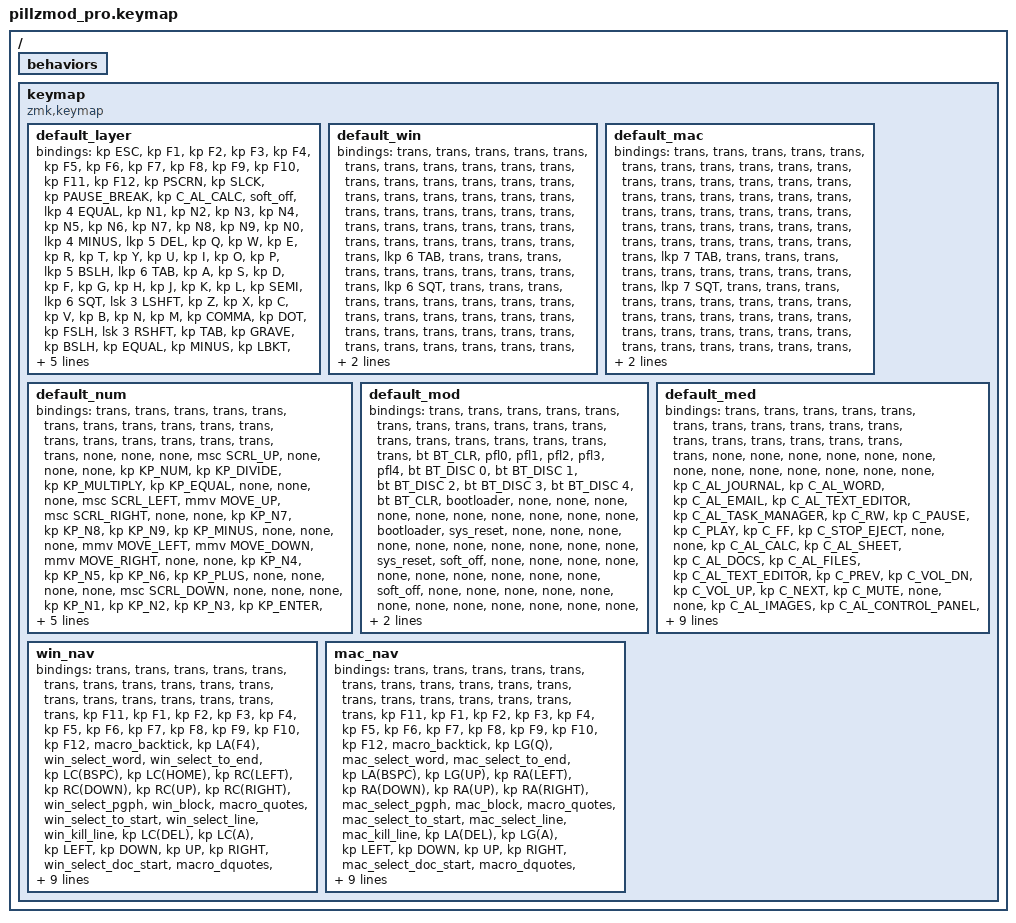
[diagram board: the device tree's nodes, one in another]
#define ZMK_POINTING_DEFAULT_MOVE_VAL 1400  // default: 600
#define ZMK_POINTING_DEFAULT_SCRL_VAL 40    // default: 10
#define USER_CONFIG_DEFAULT_KEYMAP 1        // default: keymaps

#include <behaviors.dtsi>
#include <dt-bindings/zmk/backlight.h>
#include <dt-bindings/zmk/bt.h>
#include <dt-bindings/zmk/keys.h>
#include <dt-bindings/zmk/outputs.h>
#include <dt-bindings/zmk/pointing.h>
#include "plugin/overrides.dtsi"
#include "keys.dtsi"

/ {
    behaviors {
        #include "plugin/definitions.dtsi"
        #include "plugin/declarations.dtsi"
        #include "plugin/macros.dtsi"
        #include "version.dtsi"
    };

    keymap {
        compatible = "zmk,keymap";

        default_layer {
            bindings = <
                &kp  ESC     &kp F1     &kp F2    &kp F3   &kp F4    &kp F5  &kp F6 &kp F7 &kp F8                  &kp F9 &kp F10 &kp F11 &kp F12  &kp PSCRN &kp SLCK   &kp PAUSE_BREAK &kp C_AL_CALC &soft_off
                &lkp 4 EQUAL &kp N1     &kp N2    &kp N3   &kp N4    &kp N5                                                               &kp N6   &kp N7    &kp N8     &kp N9          &kp N0        &lkp 4 MINUS
                &lkp 5 DEL   &kp Q      &kp W     &kp E    &kp R     &kp T                                                                &kp Y    &kp U     &kp I      &kp O           &kp P         &lkp 5 BSLH
                &lkp 6 TAB   &kp A      &kp S     &kp D    &kp F     &kp G                                                                &kp H    &kp J     &kp K      &kp L           &kp SEMI      &lkp 6 SQT
                &lsk 3 LSHFT &kp Z      &kp X     &kp C    &kp V     &kp B                                                                &kp N    &kp M     &kp COMMA  &kp DOT         &kp FSLH      &lsk 3 RSHFT
                             &kp TAB    &kp GRAVE &kp BSLH &kp EQUAL                                                                               &kp MINUS &kp LBKT   &kp RBKT        &kp SQT
                                                                                    &kpp LGUI DEL  &mo 4       &mo 4        &lcwp RALT 0
                                                                                                   &lkp 3 END  &lkp 3 PG_UP
                                                                   &kpl LSHFT BSPC &kpp LCTRL ESC  &lkp 6 HOME &lkp 6 PG_DN &kpp RCTRL ENTER &kpr RSHFT SPACE
                                                                                                   &kp A  &kp B &kp C
            >;
        };
        default_win {
            bindings = <
                &trans      &trans   &trans    &trans   &trans    &trans  &trans &trans &trans                  &trans &trans &trans   &trans   &trans    &trans   &trans   &trans  &trans
                &trans      &trans   &trans    &trans   &trans    &trans                                                               &trans   &trans    &trans   &trans   &trans  &trans
                &trans      &trans   &trans    &trans   &trans    &trans                                                               &trans   &trans    &trans   &trans   &trans  &trans
                &lkp 6 TAB  &trans   &trans    &trans   &trans    &trans                                                               &trans   &trans    &trans   &trans   &trans  &lkp 6 SQT
                &trans      &trans   &trans    &trans   &trans    &trans                                                               &trans   &trans    &trans   &trans   &trans  &trans
                            &trans   &trans    &trans   &trans                                                                                  &trans    &trans   &trans   &trans
                                                                                           &trans &trans  &trans &trans
                                                                                                  &trans  &trans
                                                                               &trans &trans &lkp 6 HOME  &lkp 6 PG_DN &trans &trans
                                                                                             &trans  &trans &trans
            >;
        };
        default_mac {
            bindings = <
                &trans      &trans   &trans    &trans   &trans    &trans  &trans &trans &trans                  &trans &trans &trans   &trans   &trans    &trans   &trans   &trans  &trans
                &trans      &trans   &trans    &trans   &trans    &trans                                                               &trans   &trans    &trans   &trans   &trans  &trans
                &trans      &trans   &trans    &trans   &trans    &trans                                                               &trans   &trans    &trans   &trans   &trans  &trans
                &lkp 7 TAB  &trans   &trans    &trans   &trans    &trans                                                               &trans   &trans    &trans   &trans   &trans  &lkp 7 SQT
                &trans      &trans   &trans    &trans   &trans    &trans                                                               &trans   &trans    &trans   &trans   &trans  &trans
                            &trans   &trans    &trans   &trans                                                                                  &trans    &trans   &trans   &trans
                                                                                       &trans &trans  &trans &trans
                                                                                              &trans  &trans
                                                                           &trans &trans &lkp 7 HOME  &lkp 7 PG_DN &trans &trans
                                                                                          &trans  &trans &trans
            >;
        };
        default_num {
            bindings = <
            &trans  &trans  &trans         &trans         &trans           &trans  &trans  &trans  &trans          &trans  &trans  &trans &trans  &trans         &trans          &trans          &trans        &trans
            &none   &none   &none          &msc SCRL_UP   &none            &none                                                           &none  &kp KP_NUM     &kp KP_DIVIDE   &kp KP_MULTIPLY &kp KP_EQUAL  &none
            &none   &none   &msc SCRL_LEFT &mmv MOVE_UP   &msc SCRL_RIGHT  &none                                                           &none  &kp KP_N7      &kp KP_N8       &kp KP_N9       &kp KP_MINUS  &none
            &none   &none   &mmv MOVE_LEFT &mmv MOVE_DOWN &mmv MOVE_RIGHT  &none                                                           &none  &kp KP_N4      &kp KP_N5       &kp KP_N6       &kp KP_PLUS   &none
            &none   &none   &none          &msc SCRL_DOWN &none            &none                                                           &none  &kp KP_N1      &kp KP_N2       &kp KP_N3       &kp KP_ENTER  &none
                    &none   &none          &none          &none                                                                                   &kp KP_EQUAL   &kp KP_NUMBER_0 &kp KP_DOT      &kp KP_ENTER
                                                                                              &mkp 3  &trans     &trans  &mkp 3
                                                                                                      &trans     &trans
                                                                                      &mkp 1  &mkp 2  &trans     &trans  &mkp 2  &mkp 1
                                                                                                   &trans   &trans   &trans
            >;
        };
        default_mod {
            bindings = <
            &trans      &trans       &trans       &trans       &trans       &trans  &trans  &trans  &trans   &trans  &trans &trans  &trans        &trans        &trans        &trans        &trans        &trans
            &bt BT_CLR  &pfl0        &pfl1        &pfl2        &pfl3        &pfl4                                                   &bt BT_DISC 0 &bt BT_DISC 1  &bt BT_DISC 2 &bt BT_DISC 3 &bt BT_DISC 4 &bt BT_CLR
            &bootloader &none        &none        &none        &none        &none                                                   &none         &none          &none         &none         &none         &bootloader
            &sys_reset  &none        &none        &none        &none        &none                                                   &none         &none          &none         &none         &none         &sys_reset
            &soft_off   &none        &none        &none        &none        &none                                                   &none         &none          &none         &none         &none         &soft_off
                        &none        &none        &none        &none                                                                              &none          &none         &none         &none
                                                                                                &none  &none  &none  &none
                                                                                                        &none  &none
                                                                                        &none  &none  &none  &none  &none  &none
                                                                                                &none   &none   &none
            >;
        };
        default_med {
            bindings = <
            &trans      &trans       &trans       &trans       &trans       &trans  &trans  &trans  &trans   &trans  &trans &trans  &trans        &trans        &trans        &trans        &trans        &trans
            &none &none                &none                  &none              &none                  &none                      &none       &none          &none         &none          &none                &none
            &none &kp C_AL_JOURNAL     &kp C_AL_WORD          &kp C_AL_EMAIL     &kp C_AL_TEXT_EDITOR   &kp C_AL_TASK_MANAGER      &kp C_RW    &kp C_PAUSE    &kp C_PLAY    &kp C_FF       &kp C_STOP_EJECT     &none
            &none &kp C_AL_CALC        &kp C_AL_SHEET         &kp C_AL_DOCS      &kp C_AL_FILES         &kp C_AL_TEXT_EDITOR       &kp C_PREV  &kp C_VOL_DN   &kp C_VOL_UP  &kp C_NEXT     &kp C_MUTE           &none
            &none &kp C_AL_IMAGES      &kp C_AL_CONTROL_PANEL &kp C_AL_CAL       &kp C_AL_MUSIC         &kp C_AL_WWW               &kp C_REC   &kp C_SHUFFLE  &kp C_REPEAT  &kp C_CAPTIONS &kp C_DATA_ON_SCREEN &none
                  &kp C_AL_SELECT_TASK &kp C_AL_HELP          &kp C_AL_PREV_TASK &kp C_AL_NEXT_TASK                                            &kp C_BRI_DN   &kp C_BRI_UP  &kp C_SNAPSHOT &none
                                                                                                                &trans  &trans  &trans  &trans
                                                                                                                        &trans  &trans
                                                                                                        &trans &trans  &trans  &trans  &trans &trans
                                                                                                                &trans   &trans   &trans
            >;
        };
        win_nav {
            bindings = <
        &trans           &trans               &trans             &trans              &trans          &trans  &trans  &trans  &trans  &trans  &trans  &trans  &trans       &trans          &trans          &trans         &trans                &trans
        &kp F11          &kp F1               &kp F2             &kp F3              &kp F4          &kp F5                                                  &kp F6       &kp F7          &kp F8          &kp F9         &kp F10               &kp F12
        &macro_backtick  &kp LA(F4)           &win_select_word   &win_select_to_end  &kp LC(BSPC)    &kp LC(HOME)                                            &kp RC(LEFT) &kp RC(DOWN)    &kp RC(UP)      &kp RC(RIGHT)  &win_select_pgph      &win_block
        &macro_quotes    &win_select_to_start &win_select_line   &win_kill_line      &kp LC(DEL)     &kp LC(A)                                               &kp LEFT     &kp DOWN        &kp UP          &kp RIGHT      &win_select_doc_start &macro_dquotes
        &macro_parens    &win_undo            &win_cut           &win_copy           &win_paste      &kp LC(END)                                             &kp HOME     &kp PG_DN       &kp PG_UP       &kp END        &win_select_doc_end   &macro_braces
                         &none                &macro_fatarrow    &win_join_pln       &win_join_nln                                                                        &win_open_dln   &win_open_uln   &macro_arrow   &none
                                                                                                                        &trans  &trans  &trans  &trans
                                                                                                                                &trans  &trans
                                                                                                                 &trans &trans  &trans  &trans  &trans &trans
                                                                                                                           &trans   &trans   &trans
            >;
        };
        mac_nav {
            bindings = <
        &trans           &trans               &trans             &trans              &trans          &trans  &trans  &trans  &trans  &trans  &trans  &trans  &trans       &trans          &trans          &trans         &trans                &trans
        &kp F11          &kp F1               &kp F2             &kp F3              &kp F4          &kp F5                                                  &kp F6       &kp F7          &kp F8          &kp F9         &kp F10               &kp F12
        &macro_backtick  &kp LG(Q)            &mac_select_word   &mac_select_to_end  &kp LA(BSPC)    &kp LG(UP)                                              &kp RA(LEFT) &kp RA(DOWN)    &kp RA(UP)      &kp RA(RIGHT)  &mac_select_pgph      &mac_block
        &macro_quotes    &mac_select_to_start &mac_select_line   &mac_kill_line      &kp LA(DEL)     &kp LG(A)                                               &kp LEFT     &kp DOWN        &kp UP          &kp RIGHT      &mac_select_doc_start &macro_dquotes
        &macro_parens    &mac_undo            &mac_cut           &mac_copy           &mac_paste      &kp LG(DOWN)                                            &kp RG(LEFT) &kp PG_DN       &kp PG_UP       &kp RG(RIGHT)  &mac_select_doc_end   &macro_braces
                         &none                &macro_fatarrow    &mac_join_pln       &mac_join_nln                                                                        &mac_open_dln   &mac_open_uln   &macro_arrow   &none
                                                                                                                        &trans  &trans  &trans  &trans
                                                                                                                                &trans  &trans
                                                                                                                 &trans &trans  &trans  &trans  &trans &trans
                                                                                                                           &trans   &trans   &trans
            >;
        };
    };
};
